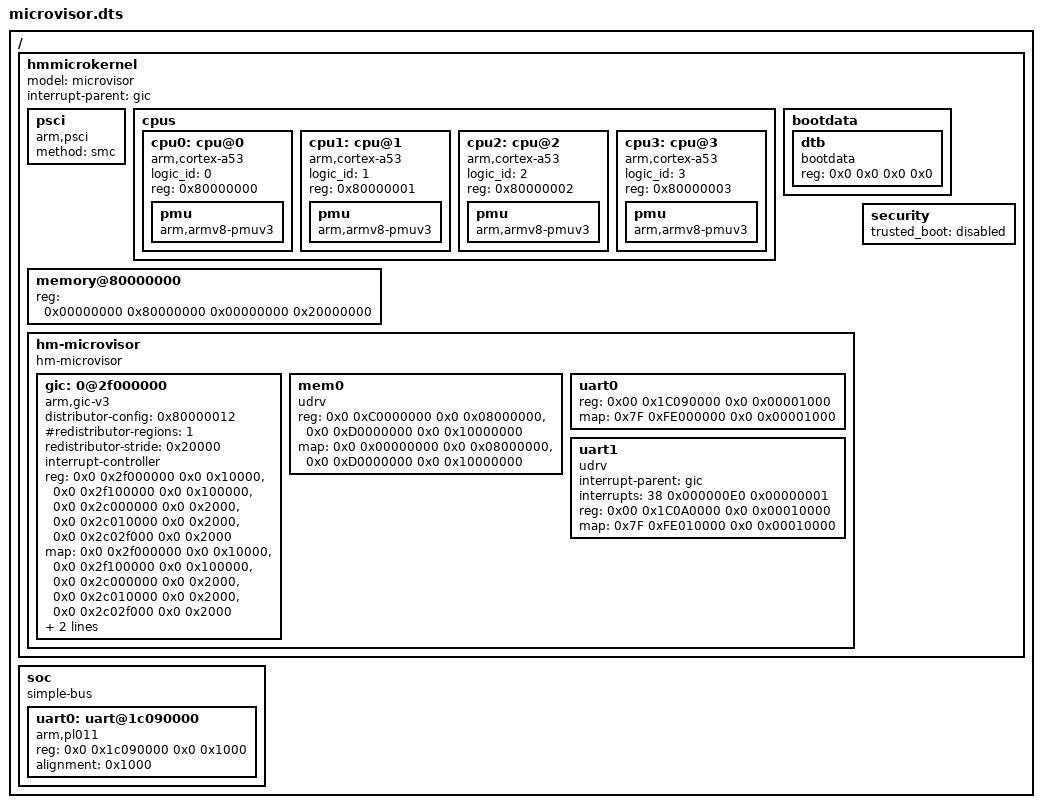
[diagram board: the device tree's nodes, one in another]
/dts-v1/;
/ { #address-cells = <2>; #size-cells = <2>; hmmicrokernel {
	model = "microvisor";
	interrupt-parent = <&gic>;
	#address-cells = <2>;
	#size-cells = <2>;

	psci {
		compatible = "arm,psci";
		method = "smc";
	};

	cpus {
		#address-cells = <1>;
		#size-cells = <0>;
		cpu0: cpu@0 {
			compatible = "arm,cortex-a53", "arm,armv8";
			device_type = "cpu";
			logic_id = <0>;
			reg = <0x80000000>;
			pmu {
				compatible = "arm,armv8-pmuv3";
			};

		};
		cpu1: cpu@1 {
			compatible = "arm,cortex-a53", "arm,armv8";
			device_type = "cpu";
			logic_id = <1>;
			reg = <0x80000001>;
			pmu {
				compatible = "arm,armv8-pmuv3";
			};

		};
		cpu2: cpu@2 {
			compatible = "arm,cortex-a53", "arm,armv8";
			device_type = "cpu";
			logic_id = <2>;
			reg = <0x80000002>;
			pmu {
				compatible = "arm,armv8-pmuv3";
			};

		};
		cpu3: cpu@3 {
			compatible = "arm,cortex-a53", "arm,armv8";
			device_type = "cpu";
			logic_id = <3>;
			reg = <0x80000003>;
			pmu {
				compatible = "arm,armv8-pmuv3";
			};

		};
	};

	memory@80000000 {
		device_type = "memory";
		reg = <0x00000000 0x80000000 0x00000000 0x20000000>;
	};

	bootdata {
		#address-cells = <2>;
		#size-cells = <2>;
		dtb {
			compatible = "bootdata", "dtb";
			/* filled by bootloader */
			reg = <0x0 0x0 0x0 0x0>;
		};
	};

	hm-microvisor {
		compatible = "hm-microvisor";
		#address-cells = <2>;
		#size-cells = <2>;

		/* See Documentation/dts-gic.md for interrupts and distributor_config */
		gic: 0@2f000000 {
			compatible = "arm,gic-v3";

			#address-cells = <2>;
			#size-cells = <2>;

			/* Enable group 0, Group1NS, Group1S, ARE_NS, ARE_S,
			 * Split EOI and Deactive mode */
			distributor-config = <0x80000012>;

			#interrupt-cells = <3>;
			#redistributor-regions = <1>;
			redistributor-stride = <0x20000>;
			interrupt-controller;

			reg =	<0x0 0x2f000000 0x0 0x10000>,	/* GICD */
				<0x0 0x2f100000 0x0 0x100000>,	/* GICR */
				<0x0 0x2c000000 0x0 0x2000>,	/* GICC */
				<0x0 0x2c010000 0x0 0x2000>,	/* GICH */
				<0x0 0x2c02f000 0x0 0x2000>;	/* GICV */
			map =	<0x0 0x2f000000 0x0 0x10000>,	/* GICD */
				<0x0 0x2f100000 0x0 0x100000>,	/* GICR */
				<0x0 0x2c000000 0x0 0x2000>,	/* GICC */
				<0x0 0x2c010000 0x0 0x2000>,	/* GICH */
				<0x0 0x2c02f000 0x0 0x2000>;	/* GICV */
			alignment = <0x10000 0x10000
				    0x10000 0x10000 0x10000>;
		};

		/* for vm0*/
		mem0 {
			compatible = "udrv";
			reg = <0x0 0xC0000000 0x0 0x08000000>,
			      <0x0 0xD0000000 0x0 0x10000000>;
			map = <0x0 0x00000000 0x0 0x08000000>,
			      <0x0 0xD0000000 0x0 0x10000000>;
		};

		uart0 {
			reg = <0x00 0x1C090000 0x0 0x00001000>;
			map = <0x7F 0xFE000000 0x0 0x00001000>;
		};

		uart1 {
			compatible = "udrv";
			interrupt-parent = <&gic>;
			interrupts = <38 0x000000E0 0x00000001>;
			reg = <0x00 0x1C0A0000 0x0 0x00010000>;
			map = <0x7F 0xFE010000 0x0 0x00010000>;
		};
	};
	security {
		trusted_boot = "disabled";
	};
	};

	soc {
		compatible = "simple-bus";
		#address-cells = <2>;
		#size-cells = <2>;
		ranges;

		uart0: uart@1c090000 {
			compatible = "arm,pl011", "arm,pl011,uart";
			reg = <0x0 0x1c090000 0x0 0x1000>;
			alignment = <0x1000>;
		};
	};
};
